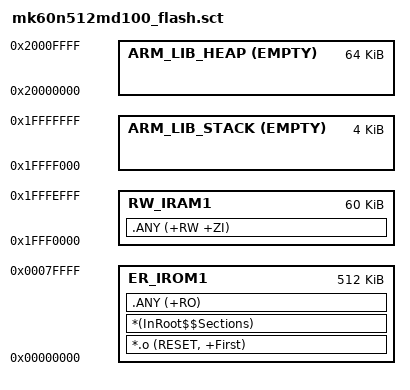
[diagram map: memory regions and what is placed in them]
;************************************************************************
;* MK60N512MD100 linker scatter file (running code from internal FLASH) *
;************************************************************************

LR_IROM1 0x00000000 0x80000
{
   ER_IROM1 0x00000000 0x80000
   {
      *.o (RESET, +First)
      *(InRoot$$Sections)
      .ANY (+RO)
   }
   
   RW_IRAM1 0x1FFF0000 0xF000
   { 
      .ANY (+RW +ZI)
   }
   
   ARM_LIB_STACK 0x20000000 EMPTY -0x1000
   {
   }
   
   ARM_LIB_HEAP 0x20000000 EMPTY 0x10000
   {
   }
}
